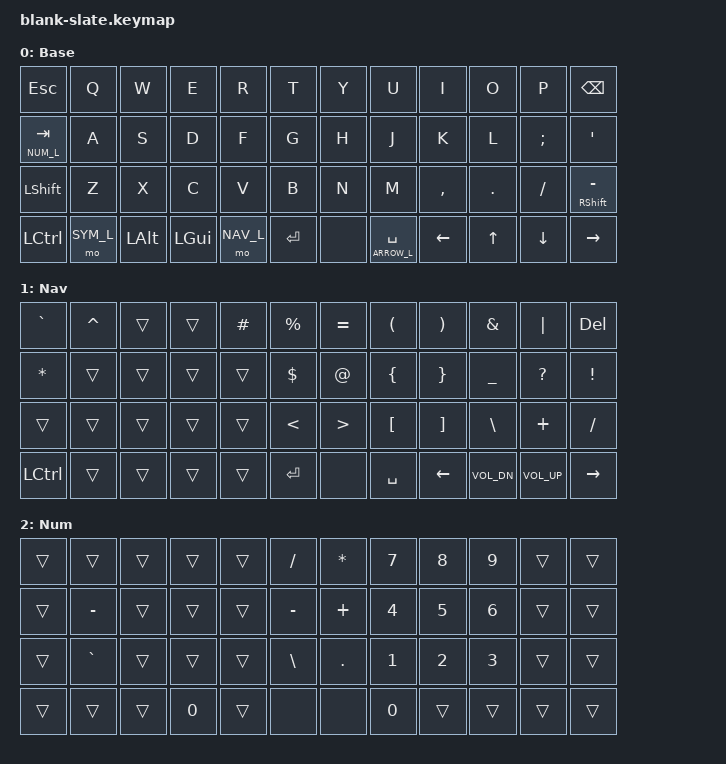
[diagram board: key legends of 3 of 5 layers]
/*
 * Copyright (c) 2025 Alvaro Restrepo
 *
 * SPDX-License-Identifier: MIT
 */

#include <behaviors.dtsi>
#include <dt-bindings/zmk/keys.h>
#include <dt-bindings/zmk/bt.h>
#include <dt-bindings/zmk/outputs.h>
#include <dt-bindings/zmk/ext_power.h>

// Layout options (using values > 10 to avoid conflictos con layer indices)
#define TBLE_ORTHO   100
// #define TBLE_MIT     101
// #define TBLE_DUAL_2U 102

// Layer definitions (starting from 0)
#define BASE_L 0
#define NAV_L 1
#define NUM_L 2
#define SYM_L 3
#define ARROW_L 4

// Using layer taps on thumbs, having quick tap as well helps w/ repeating space/backspace
&lt { quick_tap_ms = <200>; };

#define BT(n) BT_SEL n

/ {
    chosen {
       zmk,physical-layout = &layout_ortho_4x12_all1u;
    };

    macros {
      ZMK_MACRO(thumbs_up,
		wait-ms = <1>;
		tap-ms = <5>;
                bindings = <&kp PLUS &kp COLON &kp PLUS &kp N1 &kp COLON &kp RET>;
		)
    };

    tap_dances {
    	shifty: shift_caps_word {
		compatible = "zmk,behavior-tap-dance";
		label = "TD_SHIFTY";
		#binding-cells = <0>;
		tapping-term-ms = <150>;
		bindings = <&kp LSHFT>, <&caps_word>;
	};
    };

// Conditional layer only when we have less thumb keys
#ifdef TBLE_DUAL_2U
    cond_layers {
        compatible = "zmk,conditional-layers";
	tri {
	    if-layers = <NUM_L NAV_L>;
	    then-layer = <SYM_L>;
        };
    };
#endif

    keymap {
        compatible = "zmk,keymap";

        base_layer {
            label = "Base";
            bindings = <

//╭────────────┬──────────┬──────────┬──────────┬─────────────┬─────────────┬────────────────┬────────────────┬────────────┬──────────┬─────────────┬───────────────────╮
//│  Escape    │ Q        │  W       │ E        │  R          │       T     │       Y        │        U       │    I       │     O    │      P      │   Backspace       │
     &kp ESC       &kp Q      &kp W      &kp E       &kp R          &kp T          &kp Y            &kp U          &kp I       &kp O      &kp P         &kp BKSP
//├────────────┼──────────┼──────────┼──────────┼─────────────┼─────────────┼────────────────┼────────────────┼────────────┼──────────┼─────────────┼───────────────────┤
//│Tab/num_laye│  A       │  S       │ D        │  F          │       G     │       H        │        J       │    K       │     L    │      ;/:    │       ''/""       │
 &lt NUM_L TAB    &kp A      &kp S      &kp D       &kp F          &kp G          &kp H            &kp J          &kp K       &kp L      &kp SEMI      &kp QUOT
//├────────────┼──────────┼──────────┼──────────┼─────────────┼─────────────┼────────────────┼────────────────┼────────────┼──────────┼─────────────┼───────────────────┤
//│   Shift    │  Z       │  X       │ C        │  V          │       B     │       N        │        M       │    ,       │     .    │      /      │   Shift/-/_       │
   &kp LSHFT      &kp Z      &kp X      &kp C       &kp V          &kp B          &kp N            &kp M         &kp COMMA    &kp DOT    &kp FSLH      &mt RSHIFT MINUS
//├────────────┼──────────┼──────────┼──────────┼─────────────┼─────────────┼────────────────┼────────────────┼────────────┼──────────┼─────────────┼───────────────────┤
//│   CTRL     │  L_SYM   │  ALT     │ Cmd      │  L_NAV      │   Enter     │      N/A       │ L_ARROW/SPACE  │    LEFT    │     UP   │    DOWN     │   RIGHT           │
   &kp LCTRL    &mo SYM_L   &kp LALT   &kp LGUI   &mo NAV_L      &kp RET           &none       &lt ARROW_L SPACE   &kp LEFT    &kp UP     &kp DOWN      &kp RIGHT
//╰────────────┴──────────┴──────────┴──────────┴─────────────┴─────────────┴────────────────┴────────────────┴────────────┴──────────┴─────────────┴───────────────────╯
            >;
        };

        nav_layer {
            label = "Nav";
            bindings = <

//╭────────────┬──────────┬──────────┬──────────┬─────────────┬─────────────┬────────────────┬────────────────┬────────────┬──────────┬─────────────┬───────────────────╮
//│  `~        │ ^        │          │          │  #          │       %     │       =        │        (       │    )       │     &    │      |      │       DEL         │
   &kp GRAVE    &kp CARET   &trans     &trans      &kp HASH       &kp PRCNT     &kp EQUAL          &kp LPAR      &kp RPAR    &kp AMPS    &kp PIPE        &kp DEL
//├────────────┼──────────┼──────────┼──────────┼─────────────┼─────────────┼────────────────┼────────────────┼────────────┼──────────┼─────────────┼───────────────────┤
//│    *       │          │          │          │             │       $     │       @        │        {       │    }       │     _    │      ?      │       !           │
    &kp ASTRK     &trans     &trans     &trans      &trans        &kp DLLR       &kp AT           &kp LBRC        &kp RBRC   &kp UNDER    &kp QMARK      &kp EXCL
//├────────────┼──────────┼──────────┼──────────┼─────────────┼─────────────┼────────────────┼────────────────┼────────────┼──────────┼─────────────┼───────────────────┤
//│            │          │          │          │             │       <     │       >        │        [       │      ]     │    \     │      +      │       /           │
     &trans       &trans     &trans     &trans      &trans         &kp LT        &kp GT           &kp LBKT      &kp RBKT     &kp BSLH    &kp PLUS       &kp FSLH
//├────────────┼──────────┼──────────┼──────────┼─────────────┼─────────────┼────────────────┼────────────────┼────────────┼──────────┼─────────────┼───────────────────┤
//│   CTRL     │          │          │          │             │     Enter   │      N/A       │     SPACE      │    LEFT    │C_VOL_DN  │ C_VOL_UP    │        RIGHT      │
    &kp LCTRL     &trans     &trans     &trans      &trans        &kp RET         &none          &kp SPACE       &kp LEFT   &kp C_VOL_DN &kp C_VOL_UP    &kp RIGHT
//╰────────────┴──────────┴──────────┴──────────┴─────────────┴─────────────┴────────────────┴────────────────┴────────────┴──────────┴─────────────┴───────────────────╯
            >;
        };

        num_layer {
            label = "Num";
            bindings = <

//╭────────────┬──────────┬──────────┬──────────┬─────────────┬─────────────┬────────────────┬────────────────┬────────────┬──────────┬─────────────┬───────────────────╮
//│            │          │          │          │             │       /     │       *        │        7       │    8       │     9    │             │                   │
     &trans       &trans     &trans    &trans       &trans        &kp FSLH      &kp ASTRK         &kp N7        &kp N8       &kp N9       &trans        &trans
//├────────────┼──────────┼──────────┼──────────┼─────────────┼─────────────┼────────────────┼────────────────┼────────────┼──────────┼─────────────┼───────────────────┤
//│    ^       │          │          │          │             │       -     │       +        │        4       │    5       │     6    │             │                   │
     &trans      &kp MINUS   &trans     &trans      &trans       &kp MINUS      &kp PLUS         &kp N4        &kp N5       &kp N6       &trans         &trans
//├────────────┼──────────┼──────────┼──────────┼─────────────┼─────────────┼────────────────┼────────────────┼────────────┼──────────┼─────────────┼───────────────────┤
//│            │          │          │          │             │       <     │       .        │        1       │      2     │    3     │             │                   │
    &trans       &kp GRAVE   &trans     &trans      &trans       &kp BSLH        &kp DOT            &kp N1         &kp N2       &kp N3      &trans         &trans
//├────────────┼──────────┼──────────┼──────────┼─────────────┼─────────────┼────────────────┼────────────────┼────────────┼──────────┼─────────────┼───────────────────┤
//│   CTRL     │          │          │          │             │    Enter    │     N/A        │        0       │            │          │             │                   │
    &trans       &trans      &trans     &kp N0      &trans         &none          &none        &kp N0          &trans      &trans       &trans          &trans
//╰────────────┴──────────┴──────────┴──────────┴─────────────┴─────────────┴────────────────┴────────────────┴────────────┴──────────┴─────────────┴───────────────────╯

            >;
        };

        sym_layer {
            label = "Sym";
            bindings = <

//╭────────────┬──────────┬──────────┬──────────┬─────────────┬─────────────┬────────────────┬────────────────┬────────────┬──────────┬─────────────┬───────────────────╮
//│  CLEAR BT  │    BT 1  │   BT 2   │   BT 3   │    BT 4     │     BT 5    │                │                │            │          │studio_unlock│    Bootloader     │
    &bt BT_CLR   &bt BT(0)  &bt BT(1)  &bt BT(2)   &bt BT(3)     &bt BT(4)       &trans            &trans        &trans       &trans   &studio_unlock    &bootloader
//├────────────┼──────────┼──────────┼──────────┼─────────────┼─────────────┼────────────────┼────────────────┼────────────┼──────────┼─────────────┼───────────────────┤
//│    BATT    │   F1     │  F2      │  F3      │  F4         │             │                │                │            │          │             │                   │
    &bt BT_BATT    &kp F1     &kp F2     &kp F3      &kp F4        &trans        &trans             &trans        &trans       &trans       &trans        &trans
//├────────────┼──────────┼──────────┼──────────┼─────────────┼─────────────┼────────────────┼────────────────┼────────────┼──────────┼─────────────┼───────────────────┤
//│            │  F5      │  F6      │  F7      │  F8         │             │                │                │            │          │             │                   │
      &trans      &kp F5     &kp F6     &kp F7      &kp F8        &trans         &trans           &trans          &trans     &trans       &trans         &trans
//├────────────┼──────────┼──────────┼──────────┼─────────────┼─────────────┼────────────────┼────────────────┼────────────┼──────────┼─────────────┼───────────────────┤
//│            │  F9      │  F10     │  F11     │  F12        │             │     N/A        │                │            │          │             │                   │
      &trans      &kp F9     &kp F10    &kp F11    &kp F12          &trans        &none            &trans         &trans       &trans      &trans          &trans
//╰────────────┴──────────┴──────────┴──────────┴─────────────┴─────────────┴────────────────┴────────────────┴────────────┴──────────┴─────────────┴───────────────────╯

            >;
        };

			arrow_layer {
            label = "Arrow";

            bindings = <
//╭────────────┬──────────┬──────────┬──────────┬─────────────┬─────────────┬────────────────┬────────────────┬────────────┬──────────┬─────────────┬───────────────────╮
//│  `         │          │          │          │     UP      │             │                │                │            │          │             │     DEL           │
    &bt GRAVE    &trans     &trans      &trans      &kp UP         &trans         &trans          &trans         &trans       &trans    &kp LS(N4)        &kp DEL
//├────────────┼──────────┼──────────┼──────────┼─────────────┼─────────────┼────────────────┼────────────────┼────────────┼──────────┼─────────────┼───────────────────┤
//│            │          │          │  LEFT    │  DOWN       │   RIGHT     │                │                │            │          │             │                   │
    &trans       &trans     &trans     &kp LEFT   &kp DOWN      &kp RIGHT         &trans            &trans        &kp LALT   &kp LGUI      &trans           &trans
//├────────────┼──────────┼──────────┼──────────┼─────────────┼─────────────┼────────────────┼────────────────┼────────────┼──────────┼─────────────┼───────────────────┤
//│            │          │          │          │             │             │                │                │            │          │             │                   │
      &trans     &trans     &trans     &trans      &trans         &trans        &trans         &kp HOME        &kp PG_DN   &kp PG_UP    &kp END          &trans
//├────────────┼──────────┼──────────┼──────────┼─────────────┼─────────────┼────────────────┼────────────────┼────────────┼──────────┼─────────────┼───────────────────┤
//│            │          │          │          │             │                              │                │            │          │             │                   │
      &trans     &trans     &trans     &trans      &trans                &trans                  &trans           &trans      &trans      &trans           &trans
//╰────────────┴──────────┴──────────┴──────────┴─────────────┴──────────────────────────────┴────────────────┴────────────┴──────────┴─────────────┴───────────────────╯

            >;
        };


    };
};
